# STM32L4P5 register map
File version: 1.8
CPU: CM4 r0p1, little endian, MPU, FPU, 4 interrupt priority bits
Registers are 32-bit, read-write, reset 0x0 unless marked. A register's access mark holds for its fields unless they carry their own. Offsets are from the block's base; [hi:lo] are bit positions; {n}, {i} and the like mark numbered series; 'fields as' and 'values as' point back to an identical list.

## FMC — Flexible memory controller
Base 0xA0000000
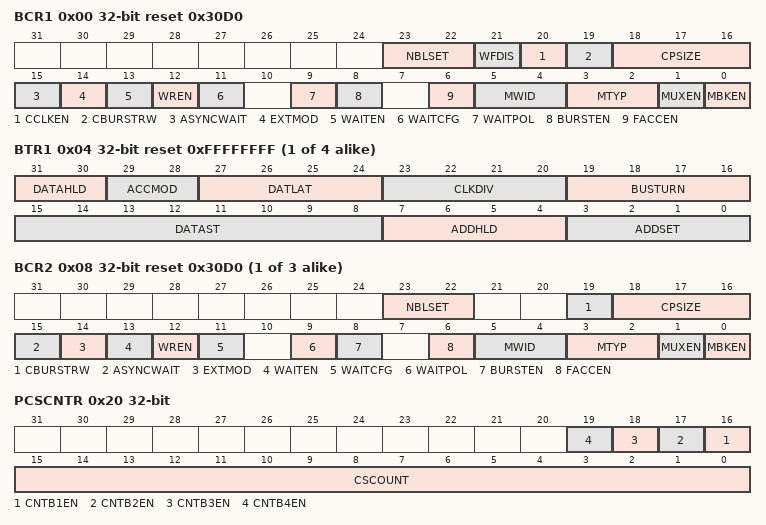
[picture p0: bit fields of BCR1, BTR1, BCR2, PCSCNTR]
0x00 BCR1 reset 0x30D0 — SRAM/NOR-Flash chip-select control register 1
  [23:22] NBLSET — Byte lane (NBL) setup
  [21] WFDIS — Write FIFO Disable
    0=Enabled (Write FIFO enabled); 1=Disabled (Write FIFO disabled)
  [20] CCLKEN
    0=Disabled (The FMC_CLK is generated continuously during asynchronous and synchronous access. The FMC_CLK clock is activated when the CCLKEN is set); 1=Enabled (The FMC_CLK is only generated during the synchronous memory access (read/write transaction))
  [19] CBURSTRW
    0=Disabled (Write operations are always performed in asynchronous mode); 1=Enabled (Write operations are performed in synchronous mode)
  [18:16] CPSIZE — CRAM page size
    0=No burst split when crossing page boundary; 1=Bytes128 (128 bytes CRAM page size); 2=Bytes256 (256 bytes CRAM page size); 3=Bytes512 (512 bytes CRAM page size); 4=Bytes1024 (1024 bytes CRAM page size)
  [15] ASYNCWAIT
    0=Disabled (Wait signal not used in asynchronous mode); 1=Enabled (Wait signal used even in asynchronous mode)
  [14] EXTMOD
    0=Disabled (Values inside the FMC_BWTR are not taken into account); 1=Enabled (Values inside the FMC_BWTR are taken into account)
  [13] WAITEN
    0=Disabled (Values inside the FMC_BWTR are taken into account); 1=Enabled (NWAIT signal enabled)
  [12] WREN
    0=Disabled (Write operations disabled for the bank by the FMC); 1=Enabled (Write operations enabled for the bank by the FMC)
  [11] WAITCFG
    0=BeforeWaitState (NWAIT signal is active one data cycle before wait state); 1=DuringWaitState (NWAIT signal is active during wait state)
  [9] WAITPOL
    0=ActiveLow (NWAIT active low); 1=ActiveHigh (NWAIT active high)
  [8] BURSTEN
    0=Disabled (Burst mode disabled); 1=Enabled (Burst mode enabled)
  [6] FACCEN
    0=Disabled (Corresponding NOR Flash memory access is disabled); 1=Enabled (Corresponding NOR Flash memory access is enabled)
  [5:4] MWID
    0=Bits8 (Memory data bus width 8 bits); 1=Bits16 (Memory data bus width 16 bits); 2=Bits32 (Memory data bus width 32 bits)
  [3:2] MTYP
    0=SRAM (SRAM memory type); 1=PSRAM (PSRAM (CRAM) memory type); 2=Flash (NOR Flash/OneNAND Flash)
  [1] MUXEN
    0=Disabled (Address/Data non-multiplexed); 1=Enabled (Address/Data multiplexed on databus)
  [0] MBKEN
    0=Disabled (Corresponding memory bank is disabled); 1=Enabled (Corresponding memory bank is enabled)
0x04 BTR{i} (i=1..4; step 0x8) reset 0xFFFFFFFF — SRAM/NOR-Flash chip-select timing register {i}
  [31:30] DATAHLD — Data hold phase duration
  [29:28] ACCMOD
    0=A (Access mode A); 1=B (Access mode B); 2=C (Access mode C); 3=D (Access mode D)
  [27:24] DATLAT
  [23:20] CLKDIV range 1..15
  [19:16] BUSTURN
  [15:8] DATAST range 1..255
  [7:4] ADDHLD range 1..15
  [3:0] ADDSET
0x08 BCR{i} (i=2..4; step 0x8) reset 0x30D0 — SRAM/NOR-Flash chip-select control register {i}
  [23:22] NBLSET — Byte lane (NBL) setup
  [19] CBURSTRW
    values as BCR1.CBURSTRW
  [18:16] CPSIZE — CRAM page size
    values as BCR1.CPSIZE
  [15] ASYNCWAIT
    values as BCR1.ASYNCWAIT
  [14] EXTMOD
    values as BCR1.EXTMOD
  [13] WAITEN
    values as BCR1.WAITEN
  [12] WREN
    values as BCR1.WREN
  [11] WAITCFG
    values as BCR1.WAITCFG
  [9] WAITPOL
    values as BCR1.WAITPOL
  [8] BURSTEN
    values as BCR1.BURSTEN
  [6] FACCEN
    values as BCR1.FACCEN
  [5:4] MWID
    values as BCR1.MWID
  [3:2] MTYP
    values as BCR1.MTYP
  [1] MUXEN
    values as BCR1.MUXEN
  [0] MBKEN
    values as BCR1.MBKEN
0x20 PCSCNTR access not given — PSRAM chip select counter register
  [n+15] CNTB{n}EN (n=1..4) — Counter Bank {n} enable
  [15:0] CSCOUNT — Chip select counter
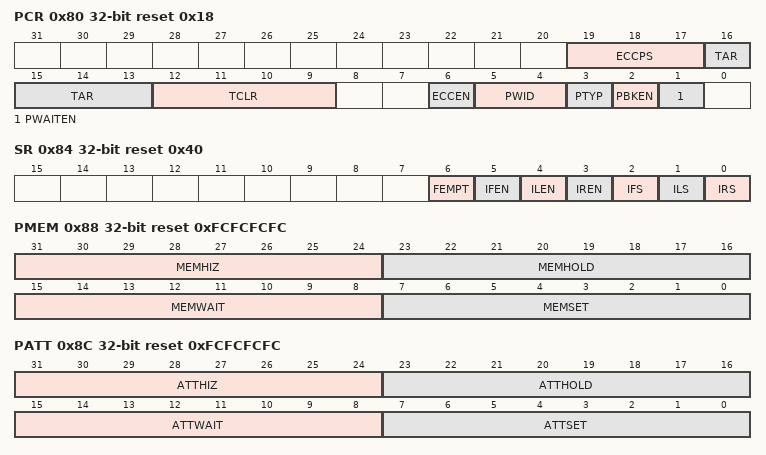
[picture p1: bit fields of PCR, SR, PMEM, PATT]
0x80 PCR reset 0x18 — PC Card/NAND Flash control register 3
  [19:17] ECCPS
    0=Bytes256 (ECC page size 256 bytes); 1=Bytes512 (ECC page size 512 bytes); 2=Bytes1024 (ECC page size 1024 bytes); 3=Bytes2048 (ECC page size 2048 bytes); 4=Bytes4096 (ECC page size 4096 bytes); 5=Bytes8192 (ECC page size 8192 bytes)
  [16:13] TAR
  [12:9] TCLR
  [6] ECCEN
    0=Disabled (ECC logic is disabled and reset); 1=Enabled (ECC logic is enabled)
  [5:4] PWID
    0=Bits8 (External memory device width 8 bits); 1=Bits16 (External memory device width 16 bits)
  [3] PTYP
    1=NANDFlash
  [2] PBKEN
    values as BCR1.MBKEN
  [1] PWAITEN
    0=Disabled (Wait feature disabled); 1=Enabled (Wait feature enabled)
0x84 SR access per field reset 0x40 — FIFO status and interrupt register 3
  [6] FEMPT ro
    0=NotEmpty (FIFO not empty); 1=Empty (FIFO empty)
  [5] IFEN rw
    0=Disabled (Interrupt falling edge detection request disabled); 1=Enabled (Interrupt falling edge detection request enabled)
  [4] ILEN rw
    0=Disabled (Interrupt high-level detection request disabled); 1=Enabled (Interrupt high-level detection request enabled)
  [3] IREN rw
    0=Disabled (Interrupt rising edge detection request disabled); 1=Enabled (Interrupt rising edge detection request enabled)
  [2] IFS rw
    0=DidNotOccur (Interrupt falling edge did not occur); 1=Occurred (Interrupt falling edge occurred)
  [1] ILS rw
    0=DidNotOccur (Interrupt high-level did not occur); 1=Occurred (Interrupt high-level occurred)
  [0] IRS rw
    0=DidNotOccur (Interrupt rising edge did not occur); 1=Occurred (Interrupt rising edge occurred)
0x88 PMEM reset 0xFCFCFCFC — Common memory space timing register 3
  [31:24] MEMHIZ range 0..254 — MEMHIZx
  [23:16] MEMHOLD range 1..254 — MEMHOLDx
  [15:8] MEMWAIT range 1..254 — MEMWAITx
  [7:0] MEMSET range 0..254 — MEMSETx
0x8C PATT reset 0xFCFCFCFC — Attribute memory space timing register 3
  [31:24] ATTHIZ range 0..254 — ATTHIZx
  [23:16] ATTHOLD range 1..254 — ATTHOLDx
  [15:8] ATTWAIT range 1..254 — ATTWAITx
  [7:0] ATTSET range 0..254 — ATTSETx
0x94 ECCR ro — ECC result register 3
  [31:0] ECC — ECCx
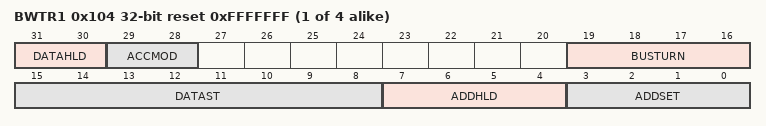
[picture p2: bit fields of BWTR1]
{0xFC+8i} BWTR{i} (i=1..4) reset 0xFFFFFFF — SRAM/NOR-Flash write timing registers {i}
  [31:30] DATAHLD — Data hold phase duration
  [29:28] ACCMOD
    values as BTR{i}.ACCMOD
  [19:16] BUSTURN — Bus turnaround phase duration
  [15:8] DATAST range 1..255
  [7:4] ADDHLD range 1..15
  [3:0] ADDSET
